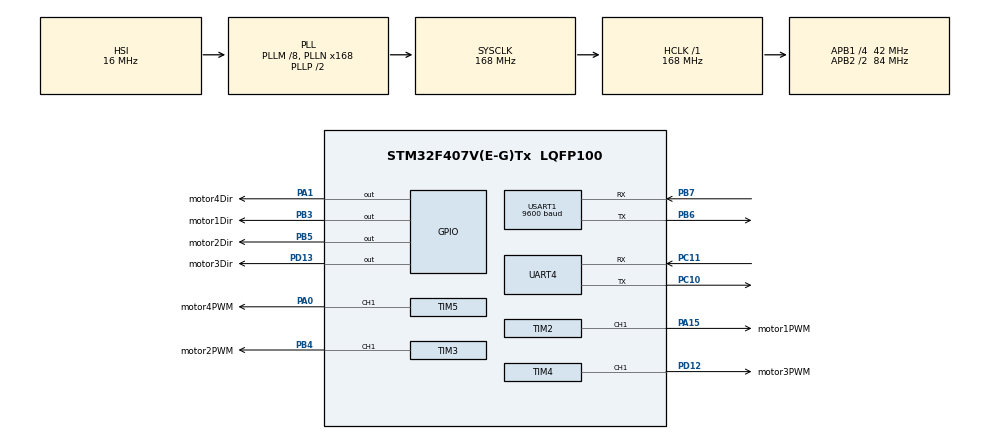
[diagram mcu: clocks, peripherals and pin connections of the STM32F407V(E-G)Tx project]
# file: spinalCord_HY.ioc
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Dma.Request0=USART1_RX
Dma.USART1_RX.0.Direction=DMA_PERIPH_TO_MEMORY
Dma.USART1_RX.0.FIFOMode=DMA_FIFOMODE_DISABLE
Dma.USART1_RX.0.Instance=DMA2_Stream2
Dma.USART1_RX.0.MemDataAlignment=DMA_MDATAALIGN_BYTE
Dma.USART1_RX.0.MemInc=DMA_MINC_ENABLE
Dma.USART1_RX.0.Mode=DMA_CIRCULAR
Dma.USART1_RX.0.PeriphDataAlignment=DMA_PDATAALIGN_BYTE
Dma.USART1_RX.0.PeriphInc=DMA_PINC_DISABLE
Dma.USART1_RX.0.Priority=DMA_PRIORITY_LOW
Mcu.Family=STM32F4
Mcu.Name=STM32F407V(E-G)Tx
Mcu.Package=LQFP100
NVIC.DMA2_Stream2_IRQn=true\:0\:0\:false\:false\:true\:false\:true
NVIC.PriorityGroup=NVIC_PRIORITYGROUP_4
NVIC.UART4_IRQn=true\:0\:0\:false\:false\:true\:true\:true
NVIC.USART1_IRQn=true\:0\:0\:false\:false\:true\:true\:true
PA0-WKUP.GPIO_Label=motor4PWM
PA0-WKUP.Signal=S_TIM5_CH1
PA1.GPIO_Label=motor4Dir
PA1.Signal=GPIO_Output
PA15.GPIO_Label=motor1PWM
PA15.Signal=S_TIM2_CH1_ETR
PB3.GPIO_Label=motor1Dir
PB3.Signal=GPIO_Output
PB4.GPIO_Label=motor2PWM
PB4.Signal=S_TIM3_CH1
PB5.GPIO_Label=motor2Dir
PB5.Signal=GPIO_Output
PB6.Mode=Asynchronous
PB6.Signal=USART1_TX
PB7.Mode=Asynchronous
PB7.Signal=USART1_RX
PC10.Mode=Asynchronous
PC10.Signal=UART4_TX
PC11.Mode=Asynchronous
PC11.Signal=UART4_RX
PD12.GPIO_Label=motor3PWM
PD12.Signal=S_TIM4_CH1
PD13.GPIO_Label=motor3Dir
PD13.Signal=GPIO_Output
ProjectManager.HeapSize=0x200
ProjectManager.StackSize=0x400
ProjectManager.TargetToolchain=STM32CubeIDE
RCC.48MHZClocksFreq_Value=84000000
RCC.AHBFreq_Value=168000000
RCC.APB1CLKDivider=RCC_HCLK_DIV4
RCC.APB1Freq_Value=42000000
RCC.APB1TimFreq_Value=84000000
RCC.APB2CLKDivider=RCC_HCLK_DIV2
RCC.APB2Freq_Value=84000000
RCC.APB2TimFreq_Value=168000000
RCC.CortexFreq_Value=168000000
RCC.HCLKFreq_Value=168000000
RCC.HSE_VALUE=25000000
RCC.HSI_VALUE=16000000
RCC.LSE_VALUE=32768
RCC.PLLM=8
RCC.PLLN=168
RCC.SYSCLKFreq_VALUE=168000000
RCC.SYSCLKSource=RCC_SYSCLKSOURCE_PLLCLK
RCC.VCOOutputFreq_Value=336000000
SH.S_TIM2_CH1_ETR.0=TIM2_CH1,PWM Generation1 CH1
SH.S_TIM3_CH1.0=TIM3_CH1,PWM Generation1 CH1
SH.S_TIM4_CH1.0=TIM4_CH1,PWM Generation1 CH1
SH.S_TIM5_CH1.0=TIM5_CH1,PWM Generation1 CH1
TIM2.Channel-PWM\ Generation1\ CH1=TIM_CHANNEL_1
TIM2.OCPolarity_1=TIM_OCPOLARITY_LOW
TIM2.Period=255
TIM2.Prescaler=505
TIM3.Channel-PWM\ Generation1\ CH1=TIM_CHANNEL_1
TIM3.OCPolarity_1=TIM_OCPOLARITY_LOW
TIM3.Period=255
TIM3.Prescaler=505
TIM4.Channel-PWM\ Generation1\ CH1=TIM_CHANNEL_1
TIM4.OCPolarity_1=TIM_OCPOLARITY_LOW
TIM4.Period=255
TIM4.Prescaler=505
TIM5.Channel-PWM\ Generation1\ CH1=TIM_CHANNEL_1
TIM5.OCPolarity_1=TIM_OCPOLARITY_LOW
TIM5.Period=255
TIM5.Prescaler=505
UART4.VirtualMode=Asynchronous
USART1.BaudRate=9600
USART1.VirtualMode=VM_ASYNC
VP_TIM2_VS_ClockSourceINT.Mode=Internal
VP_TIM3_VS_ClockSourceINT.Mode=Internal
VP_TIM4_VS_ClockSourceINT.Mode=Internal
VP_TIM5_VS_ClockSourceINT.Mode=Internal
board=custom

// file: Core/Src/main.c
/* USER CODE BEGIN Header */
/**
  ******************************************************************************
  * @file           : main.c
  * @brief          : Main program body
  ******************************************************************************
  * @attention
  *
  * <h2><center>&copy; Copyright (c) 2020 STMicroelectronics.
  * All rights reserved.</center></h2>
  *
  * This software component is licensed by ST under BSD 3-Clause license,
  * the "License"; You may not use this file except in compliance with the
  * License. You may obtain a copy of the License at:
  *                        opensource.org/licenses/BSD-3-Clause
  *
  ******************************************************************************
  */
/* USER CODE END Header */

#include "main.h"

/* USER CODE BEGIN Includes */
#include <stdlib.h>
/* USER CODE END Includes */

TIM_HandleTypeDef htim2;
TIM_HandleTypeDef htim3;
TIM_HandleTypeDef htim4;
TIM_HandleTypeDef htim5;

UART_HandleTypeDef huart4;
UART_HandleTypeDef huart1;
DMA_HandleTypeDef hdma_usart1_rx;

void SystemClock_Config(void);
static void MX_GPIO_Init(void);
static void MX_DMA_Init(void);
static void MX_USART1_UART_Init(void);
static void MX_TIM2_Init(void);
static void MX_TIM3_Init(void);
static void MX_TIM4_Init(void);
static void MX_TIM5_Init(void);
static void MX_UART4_Init(void);

/* USER CODE BEGIN 0 */
#include"DNL_SpinalCord_UART.h"
#include"DNL_SpinalCord_Motor.h"
#include"DNL_SpinalCord_Callback.h"
/* USER CODE END 0 */

int main(void)
{

  /* MCU Configuration--------------------------------------------------------*/

  /* Reset of all peripherals, Initializes the Flash interface and the Systick. */
  HAL_Init();

  /* Configure the system clock */
  SystemClock_Config();

  /* Initialize all configured peripherals */
  MX_GPIO_Init();
  MX_DMA_Init();
  MX_USART1_UART_Init();
  MX_TIM2_Init();
  MX_TIM3_Init();
  MX_TIM4_Init();
  MX_TIM5_Init();
  MX_UART4_Init();
  /* USER CODE BEGIN 2 */
  peripheralPWM_Init();
  peripheralUART_Init();
  HAL_Delay(INIT_TIME);
  /* USER CODE END 2 */

  /* Infinite loop */
  /* USER CODE BEGIN WHILE */
  while (1)
  {
	  controlMotor1(motor1Speed, motor1Dir);
	  controlMotor2(motor2Speed, motor2Dir);
	  controlMotor3(motor3Speed, motor3Dir);
	  controlMotor4(motor4Speed, motor4Dir);
    /* USER CODE END WHILE */

  }
}

void SystemClock_Config(void)
{
  RCC_OscInitTypeDef RCC_OscInitStruct = {0};
  RCC_ClkInitTypeDef RCC_ClkInitStruct = {0};

  /** Configure the main internal regulator output voltage
  */
  __HAL_RCC_PWR_CLK_ENABLE();
  __HAL_PWR_VOLTAGESCALING_CONFIG(PWR_REGULATOR_VOLTAGE_SCALE1);
  /** Initializes the CPU, AHB and APB busses clocks
  */
  RCC_OscInitStruct.OscillatorType = RCC_OSCILLATORTYPE_HSI;
  RCC_OscInitStruct.HSIState = RCC_HSI_ON;
  RCC_OscInitStruct.HSICalibrationValue = RCC_HSICALIBRATION_DEFAULT;
  RCC_OscInitStruct.PLL.PLLState = RCC_PLL_ON;
  RCC_OscInitStruct.PLL.PLLSource = RCC_PLLSOURCE_HSI;
  RCC_OscInitStruct.PLL.PLLM = 8;
  RCC_OscInitStruct.PLL.PLLN = 168;
  RCC_OscInitStruct.PLL.PLLP = RCC_PLLP_DIV2;
  RCC_OscInitStruct.PLL.PLLQ = 4;
  if (HAL_RCC_OscConfig(&RCC_OscInitStruct) != HAL_OK)
  {
    Error_Handler();
  }
  /** Initializes the CPU, AHB and APB busses clocks
  */
  RCC_ClkInitStruct.ClockType = RCC_CLOCKTYPE_HCLK|RCC_CLOCKTYPE_SYSCLK
                              |RCC_CLOCKTYPE_PCLK1|RCC_CLOCKTYPE_PCLK2;
  RCC_ClkInitStruct.SYSCLKSource = RCC_SYSCLKSOURCE_PLLCLK;
  RCC_ClkInitStruct.AHBCLKDivider = RCC_SYSCLK_DIV1;
  RCC_ClkInitStruct.APB1CLKDivider = RCC_HCLK_DIV4;
  RCC_ClkInitStruct.APB2CLKDivider = RCC_HCLK_DIV2;

  if (HAL_RCC_ClockConfig(&RCC_ClkInitStruct, FLASH_LATENCY_5) != HAL_OK)
  {
    Error_Handler();
  }
}

static void MX_TIM2_Init(void)
{

  TIM_ClockConfigTypeDef sClockSourceConfig = {0};
  TIM_MasterConfigTypeDef sMasterConfig = {0};
  TIM_OC_InitTypeDef sConfigOC = {0};

  htim2.Instance = TIM2;
  htim2.Init.Prescaler = 505;
  htim2.Init.CounterMode = TIM_COUNTERMODE_UP;
  htim2.Init.Period = 255;
  htim2.Init.ClockDivision = TIM_CLOCKDIVISION_DIV1;
  htim2.Init.AutoReloadPreload = TIM_AUTORELOAD_PRELOAD_DISABLE;
  if (HAL_TIM_Base_Init(&htim2) != HAL_OK)
  {
    Error_Handler();
  }
  sClockSourceConfig.ClockSource = TIM_CLOCKSOURCE_INTERNAL;
  if (HAL_TIM_ConfigClockSource(&htim2, &sClockSourceConfig) != HAL_OK)
  {
    Error_Handler();
  }
  if (HAL_TIM_PWM_Init(&htim2) != HAL_OK)
  {
    Error_Handler();
  }
  sMasterConfig.MasterOutputTrigger = TIM_TRGO_RESET;
  sMasterConfig.MasterSlaveMode = TIM_MASTERSLAVEMODE_DISABLE;
  if (HAL_TIMEx_MasterConfigSynchronization(&htim2, &sMasterConfig) != HAL_OK)
  {
    Error_Handler();
  }
  sConfigOC.OCMode = TIM_OCMODE_PWM1;
  sConfigOC.Pulse = 0;
  sConfigOC.OCPolarity = TIM_OCPOLARITY_LOW;
  sConfigOC.OCFastMode = TIM_OCFAST_DISABLE;
  if (HAL_TIM_PWM_ConfigChannel(&htim2, &sConfigOC, TIM_CHANNEL_1) != HAL_OK)
  {
    Error_Handler();
  }
  HAL_TIM_MspPostInit(&htim2);

}

static void MX_TIM3_Init(void)
{

  TIM_ClockConfigTypeDef sClockSourceConfig = {0};
  TIM_MasterConfigTypeDef sMasterConfig = {0};
  TIM_OC_InitTypeDef sConfigOC = {0};

  htim3.Instance = TIM3;
  htim3.Init.Prescaler = 505;
  htim3.Init.CounterMode = TIM_COUNTERMODE_UP;
  htim3.Init.Period = 255;
  htim3.Init.ClockDivision = TIM_CLOCKDIVISION_DIV1;
  htim3.Init.AutoReloadPreload = TIM_AUTORELOAD_PRELOAD_DISABLE;
  if (HAL_TIM_Base_Init(&htim3) != HAL_OK)
  {
    Error_Handler();
  }
  sClockSourceConfig.ClockSource = TIM_CLOCKSOURCE_INTERNAL;
  if (HAL_TIM_ConfigClockSource(&htim3, &sClockSourceConfig) != HAL_OK)
  {
    Error_Handler();
  }
  if (HAL_TIM_PWM_Init(&htim3) != HAL_OK)
  {
    Error_Handler();
  }
  sMasterConfig.MasterOutputTrigger = TIM_TRGO_RESET;
  sMasterConfig.MasterSlaveMode = TIM_MASTERSLAVEMODE_DISABLE;
  if (HAL_TIMEx_MasterConfigSynchronization(&htim3, &sMasterConfig) != HAL_OK)
  {
    Error_Handler();
  }
  sConfigOC.OCMode = TIM_OCMODE_PWM1;
  sConfigOC.Pulse = 0;
  sConfigOC.OCPolarity = TIM_OCPOLARITY_LOW;
  sConfigOC.OCFastMode = TIM_OCFAST_DISABLE;
  if (HAL_TIM_PWM_ConfigChannel(&htim3, &sConfigOC, TIM_CHANNEL_1) != HAL_OK)
  {
    Error_Handler();
  }
  HAL_TIM_MspPostInit(&htim3);

}

static void MX_TIM4_Init(void)
{

  TIM_ClockConfigTypeDef sClockSourceConfig = {0};
  TIM_MasterConfigTypeDef sMasterConfig = {0};
  TIM_OC_InitTypeDef sConfigOC = {0};

  htim4.Instance = TIM4;
  htim4.Init.Prescaler = 505;
  htim4.Init.CounterMode = TIM_COUNTERMODE_UP;
  htim4.Init.Period = 255;
  htim4.Init.ClockDivision = TIM_CLOCKDIVISION_DIV1;
  htim4.Init.AutoReloadPreload = TIM_AUTORELOAD_PRELOAD_DISABLE;
  if (HAL_TIM_Base_Init(&htim4) != HAL_OK)
  {
    Error_Handler();
  }
  sClockSourceConfig.ClockSource = TIM_CLOCKSOURCE_INTERNAL;
  if (HAL_TIM_ConfigClockSource(&htim4, &sClockSourceConfig) != HAL_OK)
  {
    Error_Handler();
  }
  if (HAL_TIM_PWM_Init(&htim4) != HAL_OK)
  {
    Error_Handler();
  }
  sMasterConfig.MasterOutputTrigger = TIM_TRGO_RESET;
  sMasterConfig.MasterSlaveMode = TIM_MASTERSLAVEMODE_DISABLE;
  if (HAL_TIMEx_MasterConfigSynchronization(&htim4, &sMasterConfig) != HAL_OK)
  {
    Error_Handler();
  }
  sConfigOC.OCMode = TIM_OCMODE_PWM1;
  sConfigOC.Pulse = 0;
  sConfigOC.OCPolarity = TIM_OCPOLARITY_LOW;
  sConfigOC.OCFastMode = TIM_OCFAST_DISABLE;
  if (HAL_TIM_PWM_ConfigChannel(&htim4, &sConfigOC, TIM_CHANNEL_1) != HAL_OK)
  {
    Error_Handler();
  }
  HAL_TIM_MspPostInit(&htim4);

}

static void MX_TIM5_Init(void)
{

  TIM_ClockConfigTypeDef sClockSourceConfig = {0};
  TIM_MasterConfigTypeDef sMasterConfig = {0};
  TIM_OC_InitTypeDef sConfigOC = {0};

  htim5.Instance = TIM5;
  htim5.Init.Prescaler = 505;
  htim5.Init.CounterMode = TIM_COUNTERMODE_UP;
  htim5.Init.Period = 255;
  htim5.Init.ClockDivision = TIM_CLOCKDIVISION_DIV1;
  htim5.Init.AutoReloadPreload = TIM_AUTORELOAD_PRELOAD_DISABLE;
  if (HAL_TIM_Base_Init(&htim5) != HAL_OK)
  {
    Error_Handler();
  }
  sClockSourceConfig.ClockSource = TIM_CLOCKSOURCE_INTERNAL;
  if (HAL_TIM_ConfigClockSource(&htim5, &sClockSourceConfig) != HAL_OK)
  {
    Error_Handler();
  }
  if (HAL_TIM_PWM_Init(&htim5) != HAL_OK)
  {
    Error_Handler();
  }
  sMasterConfig.MasterOutputTrigger = TIM_TRGO_RESET;
  sMasterConfig.MasterSlaveMode = TIM_MASTERSLAVEMODE_DISABLE;
  if (HAL_TIMEx_MasterConfigSynchronization(&htim5, &sMasterConfig) != HAL_OK)
  {
    Error_Handler();
  }
  sConfigOC.OCMode = TIM_OCMODE_PWM1;
  sConfigOC.Pulse = 0;
  sConfigOC.OCPolarity = TIM_OCPOLARITY_LOW;
  sConfigOC.OCFastMode = TIM_OCFAST_DISABLE;
  if (HAL_TIM_PWM_ConfigChannel(&htim5, &sConfigOC, TIM_CHANNEL_1) != HAL_OK)
  {
    Error_Handler();
  }
  HAL_TIM_MspPostInit(&htim5);

}

static void MX_UART4_Init(void)
{

  huart4.Instance = UART4;
  huart4.Init.BaudRate = 115200;
  huart4.Init.WordLength = UART_WORDLENGTH_8B;
  huart4.Init.StopBits = UART_STOPBITS_1;
  huart4.Init.Parity = UART_PARITY_NONE;
  huart4.Init.Mode = UART_MODE_TX_RX;
  huart4.Init.HwFlowCtl = UART_HWCONTROL_NONE;
  huart4.Init.OverSampling = UART_OVERSAMPLING_16;
  if (HAL_UART_Init(&huart4) != HAL_OK)
  {
    Error_Handler();
  }

}

static void MX_USART1_UART_Init(void)
{

  huart1.Instance = USART1;
  huart1.Init.BaudRate = 9600;
  huart1.Init.WordLength = UART_WORDLENGTH_8B;
  huart1.Init.StopBits = UART_STOPBITS_1;
  huart1.Init.Parity = UART_PARITY_NONE;
  huart1.Init.Mode = UART_MODE_TX_RX;
  huart1.Init.HwFlowCtl = UART_HWCONTROL_NONE;
  huart1.Init.OverSampling = UART_OVERSAMPLING_16;
  if (HAL_UART_Init(&huart1) != HAL_OK)
  {
    Error_Handler();
  }

}

static void MX_DMA_Init(void)
{

  /* DMA controller clock enable */
  __HAL_RCC_DMA2_CLK_ENABLE();

  /* DMA interrupt init */
  /* DMA2_Stream2_IRQn interrupt configuration */
  HAL_NVIC_SetPriority(DMA2_Stream2_IRQn, 0, 0);
  HAL_NVIC_EnableIRQ(DMA2_Stream2_IRQn);

}

static void MX_GPIO_Init(void)
{
  GPIO_InitTypeDef GPIO_InitStruct = {0};

  /* GPIO Ports Clock Enable */
  __HAL_RCC_GPIOA_CLK_ENABLE();
  __HAL_RCC_GPIOD_CLK_ENABLE();
  __HAL_RCC_GPIOC_CLK_ENABLE();
  __HAL_RCC_GPIOB_CLK_ENABLE();

  /*Configure GPIO pin Output Level */
  HAL_GPIO_WritePin(motor4Dir_GPIO_Port, motor4Dir_Pin, GPIO_PIN_RESET);

  /*Configure GPIO pin Output Level */
  HAL_GPIO_WritePin(motor3Dir_GPIO_Port, motor3Dir_Pin, GPIO_PIN_RESET);

  /*Configure GPIO pin Output Level */
  HAL_GPIO_WritePin(GPIOB, motor1Dir_Pin|motor2Dir_Pin, GPIO_PIN_RESET);

  /*Configure GPIO pin : motor4Dir_Pin */
  GPIO_InitStruct.Pin = motor4Dir_Pin;
  GPIO_InitStruct.Mode = GPIO_MODE_OUTPUT_PP;
  GPIO_InitStruct.Pull = GPIO_NOPULL;
  GPIO_InitStruct.Speed = GPIO_SPEED_FREQ_LOW;
  HAL_GPIO_Init(motor4Dir_GPIO_Port, &GPIO_InitStruct);

  /*Configure GPIO pin : motor3Dir_Pin */
  GPIO_InitStruct.Pin = motor3Dir_Pin;
  GPIO_InitStruct.Mode = GPIO_MODE_OUTPUT_PP;
  GPIO_InitStruct.Pull = GPIO_NOPULL;
  GPIO_InitStruct.Speed = GPIO_SPEED_FREQ_LOW;
  HAL_GPIO_Init(motor3Dir_GPIO_Port, &GPIO_InitStruct);

  /*Configure GPIO pins : motor1Dir_Pin motor2Dir_Pin */
  GPIO_InitStruct.Pin = motor1Dir_Pin|motor2Dir_Pin;
  GPIO_InitStruct.Mode = GPIO_MODE_OUTPUT_PP;
  GPIO_InitStruct.Pull = GPIO_NOPULL;
  GPIO_InitStruct.Speed = GPIO_SPEED_FREQ_LOW;
  HAL_GPIO_Init(GPIOB, &GPIO_InitStruct);

}

void Error_Handler(void)
{
}

/************************ (C) COPYRIGHT STMicroelectronics *****END OF FILE****/
